# nrf51 register map
Vendor: Nordic Semiconductor; Series: nrf51; File version: 522
CPU: CM0 r3p1, little endian, no MPU, no FPU, 2 interrupt priority bits
Registers are 32-bit, read-write, reset 0x0 unless marked. A register's access mark holds for its fields unless they carry their own. Offsets are from the block's base; [hi:lo] are bit positions; {n}, {i} and the like mark numbered series.

## CCM — AES CCM Mode Encryption.
Base 0x4000F000; alternate view of AAR
0x00 TASKS_KSGEN wo — Start generation of key-stream. This operation will stop by itself when completed.
0x04 TASKS_CRYPT wo — Start encrypt/decrypt. This operation will stop by itself when completed.
0x08 TASKS_STOP wo — Stop encrypt/decrypt.
0x100 EVENTS_ENDKSGEN — Keystream generation completed.
0x104 EVENTS_ENDCRYPT — Encrypt/decrypt completed.
0x108 EVENTS_ERROR — Error happened.
0x200 SHORTS — Shortcuts for the CCM.
  [0] ENDKSGEN_CRYPT — Shortcut between ENDKSGEN event and CRYPT task.
    0=Disabled (Shortcut disabled.); 1=Enabled (Shortcut enabled.)
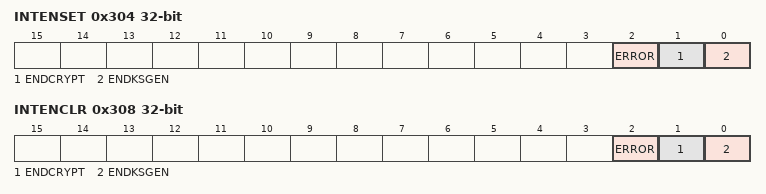
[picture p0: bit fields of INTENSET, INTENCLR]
0x304 INTENSET — Interrupt enable set register.
  [all] fields
    on read: 0=Disabled (Interrupt disabled.); 1=Enabled (Interrupt enabled.) | on write: 1=Set (Enable interrupt on write.)
  [2] ERROR — Enable interrupt on ERROR event.
  [1] ENDCRYPT — Enable interrupt on ENDCRYPT event.
  [0] ENDKSGEN — Enable interrupt on ENDKSGEN event.
0x308 INTENCLR — Interrupt enable clear register.
  [all] fields
    on read: 0=Disabled (Interrupt disabled.); 1=Enabled (Interrupt enabled.) | on write: 1=Clear (Disable interrupt on write.)
  [2] ERROR — Disable interrupt on ERROR event.
  [1] ENDCRYPT — Disable interrupt on ENDCRYPT event.
  [0] ENDKSGEN — Disable interrupt on ENDKSGEN event.
0x400 MICSTATUS ro — CCM RX MIC check result.
  [0] MICSTATUS — Result of the MIC check performed during the previous CCM RX STARTCRYPT
    0=CheckFailed (MIC check failed.); 1=CheckPassed (MIC check passed.)
0x500 ENABLE — CCM enable.
  [1:0] ENABLE
    0=Disabled (CCM is disabled.); 2=Enabled (CCM is enabled.)
0x504 MODE reset 0x1 — Operation mode.
  [0] MODE — CCM mode operation.
    0=Encryption (CCM mode TX); 1=Decryption (CCM mode TX)
0x508 CNFPTR — Pointer to a data structure holding AES key and NONCE vector.
0x50C INPTR — Pointer to the input packet.
0x510 OUTPTR — Pointer to the output packet.
0x514 SCRATCHPTR — Pointer to a scratch data area used for temporary storage during resolution. A minimum of 43 bytes must be reserved.
0xFFC POWER — Peripheral power control.
  [0] POWER
    0=Disabled (Module power disabled.); 1=Enabled (Module power enabled.)

## WDT — Watchdog Timer.
Base 0x40010000
0x00 TASKS_START wo — Start the watchdog.
0x100 EVENTS_TIMEOUT — Watchdog timeout.
0x304 INTENSET — Interrupt enable set register.
  [0] TIMEOUT — Enable interrupt on TIMEOUT event.
    on read: 0=Disabled (Interrupt disabled.); 1=Enabled (Interrupt enabled.) | on write: 1=Set (Enable interrupt on write.)
0x308 INTENCLR — Interrupt enable clear register.
  [0] TIMEOUT — Disable interrupt on TIMEOUT event.
    on read: 0=Disabled (Interrupt disabled.); 1=Enabled (Interrupt enabled.) | on write: 1=Clear (Disable interrupt on write.)
0x400 RUNSTATUS ro — Watchdog running status.
  [0] RUNSTATUS
    0=NotRunning (Watchdog timer is not running.); 1=Running (Watchdog timer is running.)
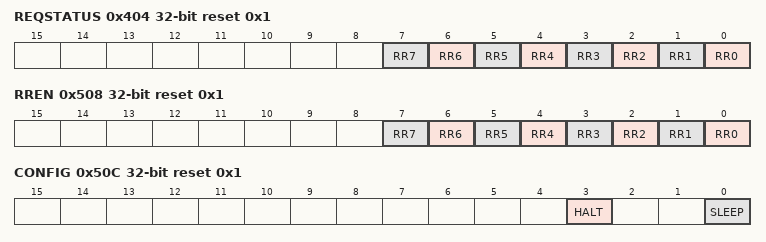
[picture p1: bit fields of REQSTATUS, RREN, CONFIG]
0x404 REQSTATUS ro reset 0x1 — Request status.
  [n] RR{n} (n=0..7) — Request status for RR[{n}].
    0=DisabledOrRequested (RR[{n}] register is not enabled or has already requested reload.); 1=EnabledAndUnrequested (RR[{n}] register is enabled and has not jet requested.)
0x504 CRV reset 0xFFFFFFFF — Counter reload value in number of 32kiHz clock cycles.
0x508 RREN reset 0x1 — Reload request enable.
  [n] RR{n} (n=0..7) — Enable or disable RR[{n}] register.
    0=Disabled (RR[{n}] register is disabled.); 1=Enabled (RR[{n}] register is enabled.)
0x50C CONFIG reset 0x1 — Configuration register.
  [3] HALT — Configure the watchdog to pause or not while the CPU is halted by the debugger.
    0=Pause watchdog while the CPU is halted by the debugger; 1=Run (Do not pause watchdog while the CPU is halted by the debugger.)
  [0] SLEEP — Configure the watchdog to pause or not while the CPU is sleeping.
    0=Pause watchdog while the CPU is asleep; 1=Run (Do not pause watchdog while the CPU is asleep.)
{0x600+4i} RR[{i}] (i=0..7) wo — Reload requests registers.
  [31:0] RR — Reload register.
    0x6E524635=Reload (Value to request a reload of the watchdog timer.)
0xFFC POWER — Peripheral power control.
  [0] POWER
    0=Disabled (Module power disabled.); 1=Enabled (Module power enabled.)
